AUTOSAR XML (schema 4-2-2)
package /ComponentTypes
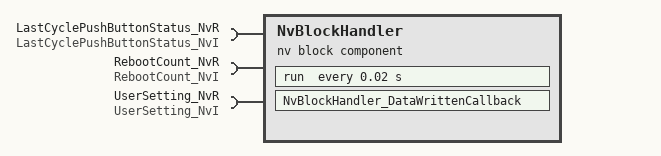
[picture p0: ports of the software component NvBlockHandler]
  nv block sw component type NvBlockHandler
    require port LastCyclePushButtonStatus_NvR: nv-require-com-spec=LastCyclePushButtonStatus, required-interface=LastCyclePushButtonStatus_NvI
    require port RebootCount_NvR: nv-require-com-spec=RebootCount, required-interface=RebootCount_NvI
    require port UserSetting_NvR: required-com-specs=[SettinNo1, SettinNo2], required-interface=UserSetting_NvI
    behavior NvBlockHandler_InternalBehavior: data-type-mapping=MappingSet
      timing event TMT_run: start-on-event=run, period=0.02
      data received event DRT_NvBlockHandler_DataWrittenCallback_RebootCount_NvR_RebootCount: start-on-event=NvBlockHandler_DataWrittenCallback, data=RebootCount_NvR.RebootCount
      data received event DRT_NvBlockHandler_DataWrittenCallback_UserSetting_NvR_SettinNo1: start-on-event=NvBlockHandler_DataWrittenCallback, data=UserSetting_NvR.SettinNo1
      data received event DRT_NvBlockHandler_DataWrittenCallback_UserSetting_NvR_SettinNo2: start-on-event=NvBlockHandler_DataWrittenCallback, data=UserSetting_NvR.SettinNo2
      port-api-options:
        enable-take-address=false, indirect-api=false, port=LastCyclePushButtonStatus_NvR
        enable-take-address=false, indirect-api=false, port=RebootCount_NvR
        enable-take-address=false, indirect-api=false, port=UserSetting_NvR
      runnable run
      runnable NvBlockHandler_DataWrittenCallback
    nv block descriptor NvBlckDescr_LastCyclePushButtonStatus_NvR_LastCyclePushButtonStatus: data-type-mapping=MappingSet, nv-block-data-mapping{nv-ram-block-element=NvBlckDescr_LastCyclePushButtonStatus_NvR_LastCyclePushButtonStatus/VariableDataPt, written-nv-data=LastCyclePushButtonStatus_NvR.LastCyclePushButtonStatus}, support-dirty-flag=true, timing-event=TMT_run
      nv block needs NvmBlockNeed:
        check-static-block-id=false
        cyclic-writing-period=0
        n-data-sets=2
        n-rom-blocks=1
        ram-block-status-control=NV-RAM-MANAGER
        readonly=false
        reliability=ERROR-DETECTION
        resistant-to-changed-sw=true
        restore-at-start=true
        store-at-shutdown=true
        store-cyclic=false
        store-emergency=false
        store-immediate=true
        use-auto-validation-at-shut-down=false
        use-crc-comp-mechanism=true
        write-only-once=false
        write-verification=true
        writing-frequency=10000
        writing-priority=LOW
      ram block VariableDataPt: type=PushButtonStatus_T
      rom block ParameterDataPt: sw-calibration-access=READ-WRITE, type=PushButtonStatus_T, init-value=constant-reference=LastCyclePushButtonStatus_IV  # Rom block long name | Rom block description
    nv block descriptor NvBlckDescr_UserSetting_NvR_SettinNo1: data-type-mapping=MappingSet, nv-block-data-mapping{nv-ram-block-element=NvBlckDescr_UserSetting_NvR_SettinNo1/VariableDataPt, written-nv-data=UserSetting_NvR.SettinNo1}, support-dirty-flag=true, timing-event=TMT_run
      nv block needs NvmBlockNeed:
        check-static-block-id=false
        cyclic-writing-period=0
        n-data-sets=2
        n-rom-blocks=1
        ram-block-status-control=NV-RAM-MANAGER
        readonly=false
        reliability=ERROR-DETECTION
        resistant-to-changed-sw=true
        restore-at-start=true
        store-at-shutdown=true
        store-cyclic=false
        store-emergency=false
        store-immediate=true
        use-auto-validation-at-shut-down=false
        use-crc-comp-mechanism=true
        write-only-once=false
        write-verification=true
        writing-frequency=10000
        writing-priority=LOW
      ram block VariableDataPt: type=UserSettingApp
      rom block ParameterDataPt: sw-calibration-access=READ-WRITE, type=UserSettingApp, init-value=constant-reference=UserSetting_IV  # Rom block long name | Rom block description
    nv block descriptor NvBlckDescr_UserSetting_NvR_SettinNo2: data-type-mapping=MappingSet, nv-block-data-mapping{nv-ram-block-element=NvBlckDescr_UserSetting_NvR_SettinNo2/VariableDataPt, written-nv-data=UserSetting_NvR.SettinNo2}, support-dirty-flag=true, timing-event=TMT_run
      nv block needs NvmBlockNeed:
        check-static-block-id=false
        cyclic-writing-period=0
        n-data-sets=2
        n-rom-blocks=1
        ram-block-status-control=NV-RAM-MANAGER
        readonly=false
        reliability=ERROR-DETECTION
        resistant-to-changed-sw=true
        restore-at-start=true
        store-at-shutdown=true
        store-cyclic=false
        store-emergency=false
        store-immediate=true
        use-auto-validation-at-shut-down=false
        use-crc-comp-mechanism=true
        write-only-once=false
        write-verification=true
        writing-frequency=10000
        writing-priority=LOW
      ram block VariableDataPt: type=UserSettingApp
      rom block ParameterDataPt: sw-calibration-access=READ-WRITE, type=UserSettingApp, init-value=constant-reference=UserSetting_IV  # Rom block long name | Rom block description
  swc implementation NvBlockHandler_Implementation: behavior=NvBlockHandler_InternalBehavior
    code-descriptors:
      code Default: artifact-descriptors=autosar-engineering-object={short-label=Default, category=SWSRC}
